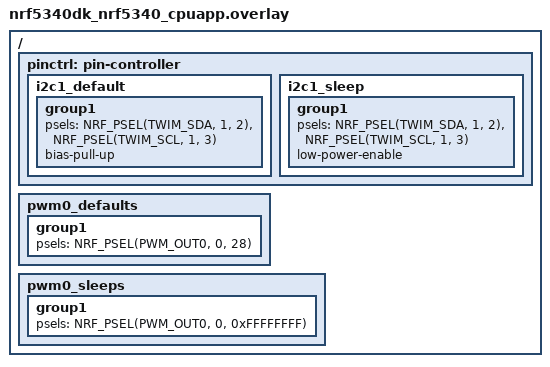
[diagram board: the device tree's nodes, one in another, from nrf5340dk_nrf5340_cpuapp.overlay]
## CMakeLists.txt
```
cmake_minimum_required(VERSION 3.13.1)

set(CMAKE_EXPORT_COMPILE_COMMANDS ON)

list(APPEND ZEPHYR_EXTRA_MODULES
  "${CMAKE_CURRENT_SOURCE_DIR}/../../../modules/wavenumber/rt_config"
)

find_package(Zephyr REQUIRED HINTS $ENV{ZEPHYR_BASE})

zephyr_library_compile_options(-fdiagnostics-color=always)

project(nxp-cup)
target_sources(app PRIVATE 
  src/main.c 
  src/ble.c
  src/motor.c
  )
```

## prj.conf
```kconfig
CONFIG_SHELL=y
CONFIG_SHELL_BACKENDS=y
CONFIG_SHELL_BACKEND_SERIAL=y
CONFIG_SHELL_BACKEND_SERIAL_INIT_PRIORITY=99
CONFIG_SHELL_PROMPT_UART="nxp-cup>"

CONFIG_SHELL_BACKEND_SERIAL_INTERRUPT_DRIVEN=n
CONFIG_SHELL_STACK_SIZE=4046
CONFIG_SHELL_BACKSPACE_MODE_DELETE=y
CONFIG_SHELL_CMD_BUFF_SIZE=256
CONFIG_SHELL_PRINTF_BUFF_SIZE=30
CONFIG_SHELL_DEFAULT_TERMINAL_WIDTH=80
CONFIG_SHELL_DEFAULT_TERMINAL_HEIGHT=24
CONFIG_SHELL_ARGC_MAX=12
CONFIG_SHELL_WILDCARD=y
CONFIG_SHELL_ECHO_STATUS=y
CONFIG_SHELL_VT100_COLORS=y
CONFIG_SHELL_METAKEYS=y
CONFIG_SHELL_HELP=y
CONFIG_SHELL_HELP_ON_WRONG_ARGUMENT_COUNT=y
CONFIG_SHELL_HISTORY=y
CONFIG_SHELL_HISTORY_BUFFER=512
CONFIG_SHELL_STATS=y
CONFIG_SHELL_CMDS=y
CONFIG_SHELL_CMDS_RESIZE=y
# CONFIG_SHELL_CMDS_SELECT is not set
# CONFIG_SHELL_LOG_BACKEND=y
CONFIG_KERNEL_SHELL=y
CONFIG_DEVICE_SHELL=y
# CONFIG_STATS is not set
# CONFIG_IMG_MANAGER is not set

CONFIG_LOG=y
CONFIG_THREAD_MONITOR=y
CONFIG_LOG=y
CONFIG_REBOOT=y
CONFIG_GPIO=y

CONFIG_I2C_SHELL=y
CONFIG_I2C=y
CONFIG_SHELL=y
CONFIG_SHELL_VT100_COLORS=y

CONFIG_BT=y
CONFIG_BT_PERIPHERAL=y
CONFIG_BT_DEVICE_NAME="I2C BLE Bridge"

CONFIG_NEWLIB_LIBC=y
CONFIG_NEWLIB_LIBC_FLOAT_SCANF=y

CONFIG_PWM=y
```

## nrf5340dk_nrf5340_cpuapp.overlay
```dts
/ {
    pinctrl: pin-controller {
        i2c1_default: i2c1_default {
            group1 {
                psels = <NRF_PSEL(TWIM_SDA, 1, 2)>,
                        <NRF_PSEL(TWIM_SCL, 1, 3)>;
                bias-pull-up;
            };
        };

        i2c1_sleep: i2c1_sleep {
            group1 {
                psels = <NRF_PSEL(TWIM_SDA, 1, 2)>,
                        <NRF_PSEL(TWIM_SCL, 1, 3)>;
                low-power-enable;
            };
        };
    };

    pwm0_defaults: pwm0_defaults {
        group1 {
            psels = <NRF_PSEL(PWM_OUT0, 0, 28)>;
        };
    };

    pwm0_sleeps: pwm0_sleeps {
        group1 {
            psels = <NRF_PSEL(PWM_OUT0, 0, 0xFFFFFFFF)>;
        };
    };
};
```

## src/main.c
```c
/*
 * Copyright (c) 2012-2014 Wind River Systems, Inc.
 *
 * SPDX-License-Identifier: Apache-2.0
 */

#include <zephyr/kernel.h>
#include <zephyr/sys/printk.h>
#include <zephyr/logging/log.h>
#include <zephyr/shell/shell.h>

#include <stdio.h>
#include <stdlib.h>

#include "ble.h"
#include "motor.h"

LOG_MODULE_REGISTER(main);

static int monkey_handler(const struct shell *shell, 
                      size_t argc,
                      char **argv)
{
   ARG_UNUSED(argc);
   ARG_UNUSED(argv);

   shell_fprintf(shell,SHELL_VT100_COLOR_YELLOW,"\r\n");
   shell_fprintf(shell,SHELL_VT100_COLOR_YELLOW,"                 ██████████████████████████            \r\n");
   shell_fprintf(shell,SHELL_VT100_COLOR_YELLOW,"               ██▒▒▒▒▒▒▒▒▒▒▒▒▒▒▒▒▒▒▒▒▒▒▒▒▒▒██          \r\n");
   shell_fprintf(shell,SHELL_VT100_COLOR_YELLOW,"               ██▒▒▒▒▒▒▒▒▒▒▒▒▒▒▒▒▒▒▒▒▒▒▒▒▒▒▒▒██        \r\n");
   shell_fprintf(shell,SHELL_VT100_COLOR_YELLOW,"             ██▒▒▒▒░░░░░░▒▒▒▒▒▒▒▒▒▒▒▒▒▒▒▒░░░░██        \r\n");
   shell_fprintf(shell,SHELL_VT100_COLOR_YELLOW,"         ██████▒▒░░░░░░░░░░▒▒▒▒▒▒▒▒▒▒▒▒░░░░░░░░██      \r\n");
   shell_fprintf(shell,SHELL_VT100_COLOR_YELLOW,"       ██░░░░░░▒▒░░░░░░░░░░░░░░░░░░░░░░░░░░░░░░██████  \r\n");
   shell_fprintf(shell,SHELL_VT100_COLOR_YELLOW,"       ██░░░░░░▒▒░░░░░░░░░░░░░░░░░░░░░░░░░░░░░░██░░░░██\r\n");
   shell_fprintf(shell,SHELL_VT100_COLOR_YELLOW,"       ██░░░░░░▒▒░░░░░░░░░░██░░░░░░░░██░░░░░░░░██░░░░██\r\n");
   shell_fprintf(shell,SHELL_VT100_COLOR_YELLOW,"         ████░░▒▒░░░░░░░░░░██░░░░░░░░██░░░░░░░░██████  \r\n");
   shell_fprintf(shell,SHELL_VT100_COLOR_YELLOW,"             ██▒▒░░░░░░░░░░░░░░░░░░░░░░░░░░░░░░██      \r\n");
   shell_fprintf(shell,SHELL_VT100_COLOR_YELLOW,"     ████      ██▒▒░░░░░░░░░░░░░░░░░░░░░░░░░░██        \r\n");
   shell_fprintf(shell,SHELL_VT100_COLOR_YELLOW,"   ██    ██      ██▒▒░░░░░░░░░░░░░░░░░░░░░░██          \r\n");
   shell_fprintf(shell,SHELL_VT100_COLOR_YELLOW,"   ██  ██      ██▒▒▒▒▒▒▒▒▒▒▒▒▒▒▒▒▒▒▒▒▒▒▒▒▒▒▒▒██        \r\n");
   shell_fprintf(shell,SHELL_VT100_COLOR_YELLOW,"   ██          ██▒▒▒▒▒▒▒▒░░░░░░░░░░░░▒▒▒▒▒▒▒▒██        \r\n");
   shell_fprintf(shell,SHELL_VT100_COLOR_YELLOW,"     ████    ██▒▒▒▒▒▒▒▒░░░░░░░░░░░░░░░░▒▒▒▒▒▒▒▒██      \r\n");
   shell_fprintf(shell,SHELL_VT100_COLOR_YELLOW,"         ██████▒▒▒▒▒▒▒▒░░░░░░░░░░░░░░░░▒▒▒▒▒▒▒▒██      \r\n");
   shell_fprintf(shell,SHELL_VT100_COLOR_YELLOW,"             ██▒▒▒▒██▒▒░░░░░░░░░░░░░░░░▒▒██▒▒▒▒██      \r\n");
   shell_fprintf(shell,SHELL_VT100_COLOR_YELLOW,"               ██████▒▒▒▒░░░░░░░░░░░░▒▒▒▒██████        \r\n");
   shell_fprintf(shell,SHELL_VT100_COLOR_YELLOW,"                   ██▒▒▒▒▒▒████████▒▒▒▒▒▒██            \r\n");
   shell_fprintf(shell,SHELL_VT100_COLOR_YELLOW,"                   ██░░░░██        ██░░░░██            \r\n");
   shell_fprintf(shell,SHELL_VT100_COLOR_YELLOW,"                   ██████            ██████            \r\n");
   shell_fprintf(shell,SHELL_VT100_COLOR_YELLOW,"\r\n");
   shell_fprintf(shell,SHELL_VT100_COLOR_CYAN,"                          I'm Super\r\n");
      
   return 0;
}

static int motor_drive_power_handler(const struct shell *shell,
                                     size_t argc,
                                     char **argv)
{
   ARG_UNUSED(argc);

   int drive_power;
   sscanf(argv[1], "%d", &drive_power);

   int wait_time;
   sscanf(argv[2], "%d", &wait_time);

   int regi;
   sscanf(argv[3], "%d", &regi);

   //The neccesary reversal for same direction movement in motors 2 and 4 specifically.
   int move[4] = {0, 1, 0, -1};
   int ret = motor_drive(regi, drive_power, wait_time, move);
   if (ret) {
      printk("motor drive write failed (%d)\n", ret);
   } else {
      printk("motor drive write successful\n");
   }

   shell_fprintf(shell, SHELL_VT100_COLOR_GREEN, "Drive Power: %d\n", drive_power);
   shell_fprintf(shell, SHELL_VT100_COLOR_GREEN, "Duration: %d\n", wait_time);
   shell_fprintf(shell, SHELL_VT100_COLOR_GREEN, "Register: %d\n", regi);

   return 0;
}

static int motor_interp_drive_handler(const struct shell *shell,
                                     size_t argc,
                                     char **argv)
{
   ARG_UNUSED(argc);

   int power_srt;
   sscanf(argv[1], "%d", &power_srt);

   int power_end;
   sscanf(argv[2], "%d", &power_end);

   int step;
   sscanf(argv[3], "%d", &step);

   int regi;
   sscanf(argv[4], "%d", &regi);

   int move[4] = {0, 1, 0, -1};
   int ret = motor_interp(regi, power_srt, power_end, step, move);
   if (ret) {
      printk("motor drive interp write failed (%d)\n", ret);
   } else {
      printk("motor drive interp write successful\n");
   }

   shell_fprintf(shell, SHELL_VT100_COLOR_GREEN, "Power Start: %d\n", power_srt);
   shell_fprintf(shell, SHELL_VT100_COLOR_GREEN, "Power End: %d\n", power_end);
   shell_fprintf(shell, SHELL_VT100_COLOR_GREEN, "Step: %d\n", step);
   shell_fprintf(shell, SHELL_VT100_COLOR_GREEN, "Register: %d\n", regi);

   return 0;
}

static int motor_interp_steer_handler(const struct shell *shell,
                                     size_t argc,
                                     char **argv)
{
   ARG_UNUSED(argc);

   int angle_srt;
   sscanf(argv[1], "%d", &angle_srt);

   int angle_end;
   sscanf(argv[2], "%d", &angle_end);


   int ret = motor_interp_servo(angle_srt, angle_end);
   if (ret) {
      printk("motor steer interp write failed (%d)\n", ret);
   } else {
      printk("motor steer interp write successful\n");
   }

   shell_fprintf(shell, SHELL_VT100_COLOR_GREEN, "Angle Start: %d\n", angle_srt);
   shell_fprintf(shell, SHELL_VT100_COLOR_GREEN, "Angle End: %d\n", angle_end);

   return 0;
}

static int motor_steer_angle_handler(const struct shell *shell,
                                     size_t argc,
                                     char **argv)
{
   ARG_UNUSED(argc);

   int angle;
   sscanf(argv[1], "%d", &angle);

   int ret = motor_servo(angle);
   if (ret) {
      printk("motor steer write failed (%d)\n", ret);
   } else {
      printk("motor steer write successful\n");
   }

   shell_fprintf(shell, SHELL_VT100_COLOR_GREEN, "Angle: %d\n", angle);
   
   return 0;
}

// Special Monkey
SHELL_CMD_REGISTER(monkey, NULL, "magic monkey", monkey_handler);

SHELL_CMD_REGISTER(motor_drive_power, NULL, "Drive the motor for a duration, duration 0 is ignored", motor_drive_power_handler);
SHELL_CMD_REGISTER(motor_interp_drive, NULL, "Move from one speed to another", motor_interp_drive_handler);
SHELL_CMD_REGISTER(motor_interp_steer, NULL, "Set steering angle", motor_interp_steer_handler);
SHELL_CMD_REGISTER(motor_steer_angle, NULL, "Set steering angle", motor_steer_angle_handler);

int main(void)
{
	printk("starting...\n\n");

   int result;

   // Checks and sets up the BLE service.
   result = ble_init();
   if (result) {
      printk("ble_init() failed\n\n");
   } else {
      printk("ble_init() successful\n\n");
   }
   
   // Checks if the I2C motor encoder device is ready.
   result = motor_init();
   if (result) {
      printk("motor_init() failed\n\n");
   } else {
      printk("motor_init() successful\n\n");
   }

	while(1)
	{  
      // Speed at which slewing the motors cuts off (Depends on the clamps)
		k_sleep(K_MSEC(5));

      motor_task();
	}
}
```

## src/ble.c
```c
/*
 * ble.c Sets up a peripheral BLE service with a characteristic for a board using
 * Zephyr BLE libraries. The purpose is to forward commands from a BLE delegate
 * to a peripheral and then translate sent data to i2c traffic.
 */

/*
 * Forwarded from:
 * Copyright (c) 2015-2016 Intel Corporation
 *
 * SPDX-License-Identifier: Apache-2.0
 */

#include <zephyr/types.h>
#include <stddef.h>
#include <string.h>
#include <stdio.h>
#include <errno.h>
#include <zephyr/sys/printk.h>
#include <zephyr/sys/byteorder.h>
#include <zephyr/kernel.h>

#include <zephyr/settings/settings.h>

#include <zephyr/bluetooth/bluetooth.h>
#include <zephyr/bluetooth/conn.h>
#include <zephyr/bluetooth/uuid.h>
#include <zephyr/bluetooth/gatt.h>
#include <zephyr/bluetooth/services/bas.h>
#include <zephyr/bluetooth/services/ias.h>

#include "motor.h"

/* Custom Service Variables */
#define BT_UUID_CUSTOM_SERVICE_VAL \
    BT_UUID_128_ENCODE(0x4fafc201, 0x1fb5, 0x459e, 0x8fcc, 0xc5c9c331915c)

static const struct bt_uuid_128 vnd_uuid = BT_UUID_INIT_128(
    BT_UUID_CUSTOM_SERVICE_VAL);

#define BT_UUID_CUSTOM_CHARACTERISTIC_VAL \
    BT_UUID_128_ENCODE(0xbeb5483e, 0x36e1, 0x4688, 0xb7f5, 0xea07361b26a8)

static const struct bt_uuid_128 vnd_char_uuid = BT_UUID_INIT_128(
    BT_UUID_CUSTOM_CHARACTERISTIC_VAL);

static const struct bt_uuid_128 vnd_enc_uuid = BT_UUID_INIT_128(
	BT_UUID_128_ENCODE(0xbeb5483e, 0x36e1, 0x4688, 0xb7f5, 0xea07361b26a8));

#define VND_MAX_LEN 20

static uint8_t vnd_value[VND_MAX_LEN + 1] = { 'V', 'e', 'n', 'd', 'o', 'r'};

static ssize_t read_vnd(struct bt_conn *conn, const struct bt_gatt_attr *attr,
			void *buf, uint16_t len, uint16_t offset)
{
	const char *value = attr->user_data;

	return bt_gatt_attr_read(conn, attr, buf, len, offset, value,
				 strlen(value));
}

// Callback for when the characteristic changes and prints it to the shell.
static void on_vnd_value_change(const struct bt_gatt_attr *attr)
{
    uint8_t *value = attr->user_data;

	char *converted_val = (char *)value;

    printk("Characteristic value changed: %s\n", value);
	printk("Converted Val: %s\n", converted_val);

	char int_str[10]; // Buffer to hold the substring as a string
    int value_as_int;

    // Ensure the end index is within bounds and that the substring is properly null-terminated
    strncpy(int_str, converted_val + 1, sizeof(int_str) - 1);
    int_str[sizeof(int_str) - 1] = '\0'; // Null-terminate the substring

    // Convert the substring to an integer
    value_as_int = atoi(int_str);

    printk("Converted integer value: %d\n", value_as_int);

	switch (converted_val[0])
	{
        case 'P':
            printk("BLE Characteristic: Drive detected\n");

			// Change atomic variable for Drive
			motor_set_state_drive_tgt(value_as_int);

            break;
        case 'S':
            printk("BLE Characteristic: Steer detected\n");

			// Change atomic variable for Steer
			motor_set_state_steer_tgt(value_as_int);

            break;
        default:
            printk("BLE Characteristic: Unhandled command detected\n");
            break;
    }
}

static ssize_t write_vnd(struct bt_conn *conn, const struct bt_gatt_attr *attr,
                         const void *buf, uint16_t len, uint16_t offset,
                         uint8_t flags)
{
    uint8_t *value = attr->user_data;

    if (offset + len > VND_MAX_LEN) {
        return BT_GATT_ERR(BT_ATT_ERR_INVALID_OFFSET);
    }

    memcpy(value + offset, buf, len);
    value[offset + len] = 0;

    on_vnd_value_change(attr);

    return len;
}

static uint8_t simulate_vnd;
static uint8_t indicating;
static struct bt_gatt_indicate_params ind_params;

static ssize_t write_without_rsp_vnd(struct bt_conn *conn,
				     const struct bt_gatt_attr *attr,
				     const void *buf, uint16_t len, uint16_t offset,
				     uint8_t flags)
{
	uint8_t *value = attr->user_data;

	if (!(flags & BT_GATT_WRITE_FLAG_CMD)) {
		/* Write Request received. Reject it since this Characteristic
		 * only accepts Write Without Response.
		 */
		return BT_GATT_ERR(BT_ATT_ERR_WRITE_REQ_REJECTED);
	}

	if (offset + len > VND_MAX_LEN) {
		return BT_GATT_ERR(BT_ATT_ERR_INVALID_OFFSET);
	}

	memcpy(value + offset, buf, len);
	value[offset + len] = 0;

	return len;
}

static void indicate_cb(struct bt_conn *conn,
			struct bt_gatt_indicate_params *params, uint8_t err)
{
	printk("Indication %s\n", err != 0U ? "fail" : "success");
}

static void indicate_destroy(struct bt_gatt_indicate_params *params)
{
	printk("Indication complete\n");
	indicating = 0U;
}

/* Vendor Primary Service Declaration */
BT_GATT_SERVICE_DEFINE(vnd_svc,
    BT_GATT_PRIMARY_SERVICE(&vnd_uuid),
    BT_GATT_CHARACTERISTIC(&vnd_char_uuid.uuid,
                           BT_GATT_CHRC_WRITE | BT_GATT_CHRC_WRITE_WITHOUT_RESP,
                           BT_GATT_PERM_WRITE, NULL,
                           write_vnd, &vnd_value),
);

static const struct bt_data ad[] = {
	BT_DATA_BYTES(BT_DATA_FLAGS, (BT_LE_AD_GENERAL | BT_LE_AD_NO_BREDR)),
	BT_DATA_BYTES(BT_DATA_UUID16_ALL,
		      BT_UUID_16_ENCODE(BT_UUID_HRS_VAL),
		      BT_UUID_16_ENCODE(BT_UUID_BAS_VAL),
		      BT_UUID_16_ENCODE(BT_UUID_CTS_VAL)),
	BT_DATA_BYTES(BT_DATA_UUID128_ALL, BT_UUID_CUSTOM_SERVICE_VAL),
};

static const struct bt_data sd[] = {
	BT_DATA(BT_DATA_NAME_COMPLETE, CONFIG_BT_DEVICE_NAME, sizeof(CONFIG_BT_DEVICE_NAME) - 1),
};

void mtu_updated(struct bt_conn *conn, uint16_t tx, uint16_t rx)
{
	printk("Updated MTU: TX: %d RX: %d bytes\n", tx, rx);
}

static struct bt_gatt_cb gatt_callbacks = {
	.att_mtu_updated = mtu_updated
};

static void connected(struct bt_conn *conn, uint8_t err)
{
	if (err) {
		printk("Connection failed (err 0x%02x)\n", err);
	} else {
		printk("Connected\n");
	}
}

static void disconnected(struct bt_conn *conn, uint8_t reason)
{
	printk("Disconnected (reason 0x%02x)\n", reason);
}

BT_CONN_CB_DEFINE(conn_callbacks) = {
	.connected = connected,
	.disconnected = disconnected,
};

static void bt_ready(void) {
    int err;

    printk("Bluetooth initialized\n");

    if (IS_ENABLED(CONFIG_SETTINGS)) {
        settings_load();
    }

    err = bt_le_adv_start(BT_LE_ADV_CONN, ad, ARRAY_SIZE(ad), sd, ARRAY_SIZE(sd));
    if (err) {
        printk("Advertising failed to start (err %d)\n", err);
        return;
    }

    printk("Advertising successfully started\n");
}

int ble_init(void)
{
	struct bt_gatt_attr *vnd_ind_attr;
	char str[BT_UUID_STR_LEN];
	int err;

	err = bt_enable(NULL);
	if (err) {
		printk("Bluetooth init failed (err %d)\n", err);
		return 0;
	}

	bt_ready();

	bt_gatt_cb_register(&gatt_callbacks);

	vnd_ind_attr = bt_gatt_find_by_uuid(vnd_svc.attrs, vnd_svc.attr_count,
					    &vnd_enc_uuid.uuid);
	bt_uuid_to_str(&vnd_enc_uuid.uuid, str, sizeof(str));
	printk("Indicate VND attr %p (UUID %s)\n", vnd_ind_attr, str);

	/* Implement notification. At the moment there is no suitable way
	 * of starting delayed work so we do it here
	 */

	/*
	while (1) {
		k_sleep(K_SECONDS(1));
		if (simulate_vnd && vnd_ind_attr) {
			if (indicating) {
				continue;
			}

			ind_params.attr = vnd_ind_attr;
			ind_params.func = indicate_cb;
			ind_params.destroy = indicate_destroy;
			ind_params.data = &indicating;
			ind_params.len = sizeof(indicating);

			if (bt_gatt_indicate(NULL, &ind_params) == 0) {
				indicating = 1U;
			}
		}
	}
	*/

	return 0;
}
```

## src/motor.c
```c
#include <zephyr/drivers/i2c.h>
#include <zephyr/device.h>
#include <zephyr/sys/util.h>
#include <stdint.h>
#include <math.h>
#include <zephyr/kernel.h>

#include <zephyr/drivers/pwm.h>
#include <zephyr/logging/log.h>
#include <zephyr/zephyr.h>

#include <zephyr/sys/atomic.h>

// I2C ADDRESS TESTING
//#define I2C_ADDR 0x04 //AARDVARK
#define I2C_ADDR 0x34 //MOTOR ENCODER

// Threading for Motor Interpolation
#define THREAD_STACK_SIZE 1024
#define THREAD_PRIORITY K_PRIO_PREEMPT(1)

// PWM defines
#define PWM_NODE DT_NODELABEL(pwm0)
#define PWM_CHANNEL 0                   /* Channel 0 corresponds to PWM_OUT0 */
#define PWM_PERIOD_USEC 2.857 * 1000 * 1000    // Mimic 350Hz frequency
#define PWM_POLARITY_NORMAL 0           // Normal polarity for the PWM signal
#define SLEW 1                         // Slew rate to move Servo

#define STEER_CLAMP 90

// Statics for storing the state POWER and ANGLE of the motors in the car
static int state_drive = 0;
static int state_steer = 0; 

// Atomics for storing target data (The target states of the system) (POWER and ANGLE)
atomic_t state_drive_tgt = ATOMIC_INIT(0);
atomic_t state_steer_tgt = ATOMIC_INIT(0);

const struct device *i2c_dev = DEVICE_DT_GET(DT_NODELABEL(i2c1));

K_THREAD_STACK_DEFINE(thread_stack, THREAD_STACK_SIZE);
static struct k_thread stop_thread_data;

// Initialize all the motors before use
int motor_init(void)
{
    if (!device_is_ready(i2c_dev)) {
        printk("motor_init: Device is not ready.\n");
        return -ENODEV;
    } else {
        printk("motor_init: Device is ready.\n");
    }
    return 0;

    // Sweep the steering motor to catch current state and set it to 0
    const struct device *pwm_dev;
    pwm_dev = DEVICE_DT_GET(PWM_NODE);
    int ret;
    for(int sweep = 1000000; sweep <= 2000000; sweep+= 1000) {
        ret = pwm_set(pwm_dev, PWM_CHANNEL, PWM_PERIOD_USEC, sweep, NULL);
        k_sleep(K_MSEC(SLEW));
    }
    // Sweep with motor locked back to home
    for(int sweep = 2000000; sweep >= 1500000; sweep-= 1000) {
        ret = pwm_set(pwm_dev, PWM_CHANNEL, PWM_PERIOD_USEC, sweep, NULL);
        k_sleep(K_MSEC(SLEW));
    }
    if(ret) {
        printk("motor_init: Error in Calibration.\n");
        return ret;
    } else {
        printk("motor_init: Steering ready.\n");
        return 0;
    }
}

// Thread function to perform the stop I2C operation
void motor_stop_thread_function(void *i2c_dev_ptr, void *regi_ptr, void *duration_ptr)
{
    const struct device *i2c_dev = (const struct device *)i2c_dev_ptr;
    int *regi_use = (uint8_t *)regi_ptr;
    int duration = *(int *)duration_ptr;

    uint8_t stop_data[] = {regi_use, 0x00, 0x00, 0x00, 0x00};
    k_sleep(K_MSEC(duration * 1000)); // Sleep for the specified duration
    i2c_write(i2c_dev, stop_data, 5, I2C_ADDR); // Write the stop data
}

// Function to manually set the power for the drive motors
int motor_drive(int regi, int power, int duration, int active_group[4]) 
{
    int recc_regi = 0x33; //(int)51 for motor encoder to drive motors.
    double abs_limits = 53.0; // Found through experiment.

    int regi_use;
    if(regi == 0) {
        regi_use = recc_regi;
        printk("motor_drive: Using default register 0x%X\n", regi_use);
    } else {
        regi_use = regi;
        printk("motor_drive: Using custom register: 0x%X\n", regi_use);
    }

    // Int power comes in as a number -100 < power < 100.
    // Needs to be constrained to an integer between 53 and -53 using the abs_limits.
    int scaled_power = (int)round((double)power * (abs_limits / 100.0));

    // active_group[4] comes in as an array of ints {0, 1, 0 -1} for instance.
    uint8_t data[] = {regi_use, (uint8_t)(active_group[0] * scaled_power),
                            (uint8_t)(active_group[1] * scaled_power),
                            (uint8_t)(active_group[2] * scaled_power),
                            (uint8_t)(active_group[3] * scaled_power)};
    
    printk("motor_drive: Scaled Power: %d\n", scaled_power);
    // Perform the I2C write operation
    int ret = i2c_write(i2c_dev, data, ARRAY_SIZE(data), I2C_ADDR);
    if (duration > 0) {
        k_tid_t thread_id = k_thread_create(&stop_thread_data, thread_stack, THREAD_STACK_SIZE,
                        motor_stop_thread_function, (void *)i2c_dev, (void *)regi_use, (void *)&duration,
                        THREAD_PRIORITY, 0, K_NO_WAIT);
        if (thread_id == NULL) {
            printk("motor_drive: Failed to create thread\n");
        } else {
            printk("motor_drive: Thread created successfully\n");
        }
    }

    return ret;
}

// Function to manually move the drive motors to a speed raming up from a start power to end power
int motor_interp(int regi, int start_pwr, int end_pwr, int step, int active_group[4])
{
    int recc_regi = 0x33; //(int)51 for motor encoder to drive motors.
    double abs_limits = 53.0; // Found through experiment.

    int regi_use;
    if(regi == 0) {
        regi_use = recc_regi;
        printk("motor_interp: Using default register 0x%X\n", regi_use);
    } else {
        regi_use = regi;
        printk("motor_interp: Using custom register: 0x%X\n", regi_use);
    }

    // Int power comes in as a number -100 < power < 100.
    // Needs to be constrained to an integer between 53 and -53 using the abs_limits.
    int scaled_srt_power = (int)round((double)start_pwr * (abs_limits / 100.0));
    int scaled_end_power = (int)round((double)end_pwr * (abs_limits / 100.0));

    int ret = 0;
    if(scaled_srt_power < scaled_end_power)
    {
        for(int drive_power = scaled_srt_power; drive_power <= scaled_end_power; drive_power++)
        {
            uint8_t data[] = {regi_use, (uint8_t)(active_group[0] * drive_power),
                            (uint8_t)(active_group[1] * drive_power),
                            (uint8_t)(active_group[2] * drive_power),
                            (uint8_t)(active_group[3] * drive_power)};
            int ret = i2c_write(i2c_dev, data, ARRAY_SIZE(data), I2C_ADDR);
            k_sleep(K_MSEC(step));
        }
    } else {
        for(int drive_power = scaled_srt_power; drive_power >= scaled_end_power; drive_power--)
        {
            uint8_t data[] = {regi_use, (uint8_t)(active_group[0] * drive_power),
                            (uint8_t)(active_group[1] * drive_power),
                            (uint8_t)(active_group[2] * drive_power),
                            (uint8_t)(active_group[3] * drive_power)};
            int ret = i2c_write(i2c_dev, data, ARRAY_SIZE(data), I2C_ADDR);
            k_sleep(K_MSEC(step));
        }
    }

    return ret;
}

// Function to manually move the steering servo to a desired end angle while catching a range of angles inbetween the start and end
int motor_interp_servo(int angle_srt, int angle_end)
{
    const struct device *pwm_dev;
    int pulse_width_srt;
    int pulse_width_end;
    int ret;

    // Get the PWM device from the device tree
    pwm_dev = DEVICE_DT_GET(PWM_NODE);
    if (!device_is_ready(pwm_dev)) {
        printk("motor_interp_servo: PWM device %s is not ready", pwm_dev->name);
        return -ENODEV; // Return an error code if the device is not ready
    }

    // Calculate pulse width based on the angle
    pulse_width_srt = 1000*(int)round(1000 + (angle_srt + STEER_CLAMP) * (1000 / (STEER_CLAMP * 2)));
    pulse_width_end = 1000*(int)round(1000 + (angle_end + STEER_CLAMP) * (1000 / (STEER_CLAMP * 2)));

    if(pulse_width_srt < pulse_width_end)
    {
        for(int pulse_width = pulse_width_srt; pulse_width <= pulse_width_end; pulse_width+= 1000)
        {
            k_sleep(K_MSEC(SLEW));
            int ret = pwm_set(pwm_dev, PWM_CHANNEL, PWM_PERIOD_USEC, pulse_width, NULL);
        }
    } else {
        for(int pulse_width = pulse_width_srt; pulse_width >= pulse_width_end; pulse_width-= 1000)
        {
            k_sleep(K_MSEC(SLEW));
            int ret = pwm_set(pwm_dev, PWM_CHANNEL, PWM_PERIOD_USEC, pulse_width, NULL);
        }
    }
    if (ret) {
        printk("motor_interp_servo: Failed to set PWM signal. Error %d", ret);
        return ret; // Return the error code if setting PWM fails
    }

    printk("motor_interp_servo: PWM pulse width set to %d ns for angle %d degrees\n", pulse_width_end, angle_end);
    return 0; // Return 0 for success
}

// Function to manually set the steering servo to an angle
int motor_servo(int angle)
{
    const struct device *pwm_dev;
    int pulse_width;
    int ret;

    // Get the PWM device from the device tree
    pwm_dev = DEVICE_DT_GET(PWM_NODE);
    if (!device_is_ready(pwm_dev)) {
        printk("motor_servo: PWM device %s is not ready", pwm_dev->name);
        return -ENODEV; // Return an error code if the device is not ready
    }

    // Calculate pulse width based on the angle
    pulse_width = 1000*(int)round(1000 + (angle + STEER_CLAMP) * (1000 / (STEER_CLAMP * 2)));
    ret = pwm_set(pwm_dev, PWM_CHANNEL, PWM_PERIOD_USEC, pulse_width, NULL);

    if (ret) {
        printk("motor_servo: Failed to set PWM signal. Error %d", ret);
        return ret; // Return the error code if setting PWM fails
    }

    printk("motor_servo: PWM pulse width set to %d ns for angle %d degrees\n", pulse_width, angle);
    return 0; // Return 0 for success
}

// Function to look at deltas between both steering and drive variable to slew them towards their command variables
int motor_task()
{
    int ret;
    static int move[4] = {0, 1, 0, -1};

    if(atomic_get(&state_steer_tgt) > state_steer)
    {
        state_steer++;
    } else if(atomic_get(&state_steer_tgt) < state_steer) {
        state_steer--;
    } else {
        // Keep the steer state the same.
    }
    if(atomic_get(&state_steer_tgt) != state_steer)
    {
        ret = motor_servo(state_steer);
        printk("motor_task: steer tgt: %d\n", atomic_get(&state_steer_tgt));
        printk("motor_task: steer: %d\n", state_steer);
    }

    if(atomic_get(&state_drive_tgt) > state_drive)
    {
        state_drive++;
    } else if(atomic_get(&state_drive_tgt) > state_drive) {
        state_drive--;
    } else {
        // Keep the Drive State the same.
    }
    if(atomic_get(&state_drive_tgt) != state_drive)
    {
        ret = motor_drive(0x33, state_drive, 0x00, move);
    }

    return ret;
}

int motor_set_state_steer_tgt(int tgt)
{
    atomic_set(&state_steer_tgt, tgt);
}

int motor_set_state_drive_tgt(int tgt)
{
    atomic_set(&state_drive_tgt, tgt);
}
```

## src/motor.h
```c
int motor_init(void);
int motor_drive(int regi, int power, int duration, int active_group[4]);
int motor_interp(int regi, int start_pwr, int end_pwr, int step, int active_group[4]);
int motor_interp_servo(int angle_srt, int angle_end);
int motor_servo(int angle);

int motor_set_state_steer_tgt(int tgt);
int motor_set_state_drive_tgt(int tgt);
```
